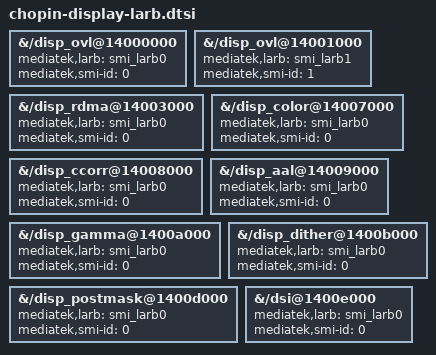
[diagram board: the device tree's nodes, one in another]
// SPDX-License-Identifier: GPL-2.0-only
/*
 * chopin: larb and smi-id wiring for the display.
 */

&{/disp_ovl@14000000} { mediatek,larb = <&smi_larb0>; mediatek,smi-id = <0>; };
&{/disp_ovl@14001000} { mediatek,larb = <&smi_larb1>; mediatek,smi-id = <1>; };
&{/disp_rdma@14003000}   { mediatek,larb = <&smi_larb0>;
	mediatek,smi-id = <0>;
};
&{/disp_color@14007000}  { mediatek,larb = <&smi_larb0>;
	mediatek,smi-id = <0>;
};
&{/disp_ccorr@14008000}  { mediatek,larb = <&smi_larb0>;
	mediatek,smi-id = <0>;
};
&{/disp_aal@14009000} { mediatek,larb = <&smi_larb0>; mediatek,smi-id = <0>; };
&{/disp_gamma@1400a000}  { mediatek,larb = <&smi_larb0>;
	mediatek,smi-id = <0>;
};
&{/disp_dither@1400b000} { mediatek,larb = <&smi_larb0>; mediatek,smi-id = <0>; };
&{/disp_postmask@1400d000} { mediatek,larb = <&smi_larb0>; mediatek,smi-id = <0>; };
&{/dsi@1400e000}         { mediatek,larb = <&smi_larb0>;
	mediatek,smi-id = <0>;
};

/*
 * Bring-up panel node: the reference tree's l16 driver is used only so the v2
 * DSI stops deferring ("Waiting for bridge or panel driver"); the k10a's own
 * init sequence / DSC parameters must replace it next.
 */
